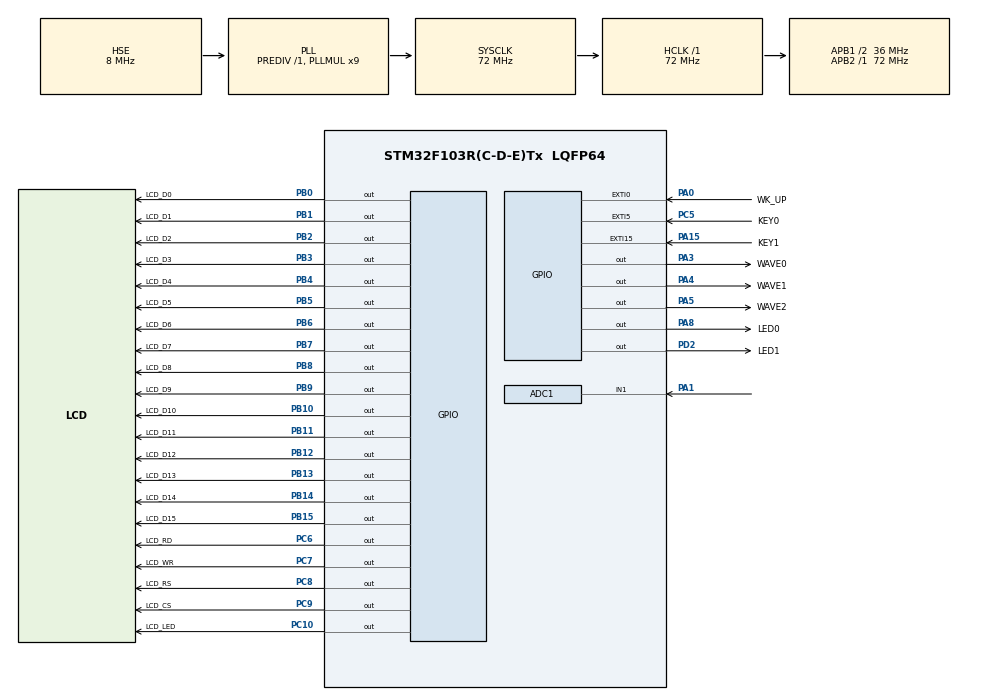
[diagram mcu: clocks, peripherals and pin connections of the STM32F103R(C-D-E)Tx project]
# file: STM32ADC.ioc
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ADC1.Channel-1\#ChannelRegularConversion=ADC_CHANNEL_1
ADC1.ContinuousConvMode=DISABLE
ADC1.EnableAnalogWatchDog=false
ADC1.EnableInjectedConversion=DISABLE
ADC1.EnableRegularConversion=ENABLE
ADC1.ExternalTrigConv=ADC_EXTERNALTRIGCONV_T3_TRGO
ADC1.InjNumberOfConversion=1
ADC1.NbrOfConversion=1
ADC1.NbrOfConversionFlag=1
ADC1.Rank-1\#ChannelRegularConversion=1
ADC1.SamplingTime-1\#ChannelRegularConversion=ADC_SAMPLETIME_7CYCLES_5
ADC1.master=1
Dma.ADC1.0.Direction=DMA_PERIPH_TO_MEMORY
Dma.ADC1.0.Instance=DMA1_Channel1
Dma.ADC1.0.MemDataAlignment=DMA_MDATAALIGN_HALFWORD
Dma.ADC1.0.MemInc=DMA_MINC_ENABLE
Dma.ADC1.0.Mode=DMA_CIRCULAR
Dma.ADC1.0.PeriphDataAlignment=DMA_PDATAALIGN_HALFWORD
Dma.ADC1.0.PeriphInc=DMA_PINC_DISABLE
Dma.ADC1.0.Priority=DMA_PRIORITY_VERY_HIGH
Dma.Request0=ADC1
Mcu.Family=STM32F1
Mcu.Name=STM32F103R(C-D-E)Tx
Mcu.Package=LQFP64
NVIC.DMA1_Channel1_IRQn=true\:1\:0\:true\:false\:true\:false\:true
NVIC.EXTI15_10_IRQn=true\:2\:2\:true\:false\:true\:true\:true
NVIC.EXTI9_5_IRQn=true\:2\:1\:true\:false\:true\:true\:true
NVIC.PriorityGroup=NVIC_PRIORITYGROUP_2
PA0-WKUP.GPIO_Label=WK_UP
PA0-WKUP.GPIO_ModeDefaultEXTI=GPIO_MODE_IT_RISING
PA0-WKUP.GPIO_PuPd=GPIO_PULLDOWN
PA0-WKUP.Signal=GPXTI0
PA1.Signal=ADCx_IN1
PA13.Mode=Serial_Wire
PA13.Signal=SYS_JTMS-SWDIO
PA14.Mode=Serial_Wire
PA14.Signal=SYS_JTCK-SWCLK
PA15.GPIO_Label=KEY1
PA15.GPIO_ModeDefaultEXTI=GPIO_MODE_IT_FALLING
PA15.GPIO_PuPd=GPIO_PULLUP
PA15.Signal=GPXTI15
PA3.GPIO_Label=WAVE0
PA3.Signal=GPIO_Output
PA4.GPIO_Label=WAVE1
PA4.Signal=GPIO_Output
PA5.GPIO_Label=WAVE2
PA5.Signal=GPIO_Output
PA8.GPIO_Label=LED0
PA8.Signal=GPIO_Output
PB0.GPIO_Label=LCD_D0
PB0.GPIO_ModeDefaultOutputPP=GPIO_MODE_OUTPUT_PP
PB0.GPIO_PuPd=GPIO_PULLUP
PB0.GPIO_Speed=GPIO_SPEED_FREQ_HIGH
PB0.PinState=GPIO_PIN_SET
PB0.Signal=GPIO_Output
PB1.GPIO_Label=LCD_D1
PB1.GPIO_PuPd=GPIO_PULLUP
PB1.GPIO_Speed=GPIO_SPEED_FREQ_HIGH
PB1.PinState=GPIO_PIN_SET
PB1.Signal=GPIO_Output
PB10.GPIO_Label=LCD_D10
PB10.GPIO_PuPd=GPIO_PULLUP
PB10.GPIO_Speed=GPIO_SPEED_FREQ_HIGH
PB10.PinState=GPIO_PIN_SET
PB10.Signal=GPIO_Output
PB11.GPIO_Label=LCD_D11
PB11.GPIO_PuPd=GPIO_PULLUP
PB11.GPIO_Speed=GPIO_SPEED_FREQ_HIGH
PB11.PinState=GPIO_PIN_SET
PB11.Signal=GPIO_Output
PB12.GPIO_Label=LCD_D12
PB12.GPIO_PuPd=GPIO_PULLUP
PB12.GPIO_Speed=GPIO_SPEED_FREQ_HIGH
PB12.PinState=GPIO_PIN_SET
PB12.Signal=GPIO_Output
PB13.GPIO_Label=LCD_D13
PB13.GPIO_PuPd=GPIO_PULLUP
PB13.GPIO_Speed=GPIO_SPEED_FREQ_HIGH
PB13.PinState=GPIO_PIN_SET
PB13.Signal=GPIO_Output
PB14.GPIO_Label=LCD_D14
PB14.GPIO_PuPd=GPIO_PULLUP
PB14.GPIO_Speed=GPIO_SPEED_FREQ_HIGH
PB14.PinState=GPIO_PIN_SET
PB14.Signal=GPIO_Output
PB15.GPIO_Label=LCD_D15
PB15.GPIO_PuPd=GPIO_PULLUP
PB15.GPIO_Speed=GPIO_SPEED_FREQ_HIGH
PB15.PinState=GPIO_PIN_SET
PB15.Signal=GPIO_Output
PB2.GPIO_Label=LCD_D2
PB2.GPIO_PuPd=GPIO_PULLUP
PB2.GPIO_Speed=GPIO_SPEED_FREQ_HIGH
PB2.PinState=GPIO_PIN_SET
PB2.Signal=GPIO_Output
PB3.GPIO_Label=LCD_D3
PB3.GPIO_ModeDefaultOutputPP=GPIO_MODE_OUTPUT_PP
PB3.GPIO_PuPd=GPIO_PULLUP
PB3.GPIO_Speed=GPIO_SPEED_FREQ_HIGH
PB3.PinState=GPIO_PIN_SET
PB3.Signal=GPIO_Output
PB4.GPIO_Label=LCD_D4
PB4.GPIO_PuPd=GPIO_PULLUP
PB4.GPIO_Speed=GPIO_SPEED_FREQ_HIGH
PB4.PinState=GPIO_PIN_SET
PB4.Signal=GPIO_Output
PB5.GPIO_Label=LCD_D5
PB5.GPIO_PuPd=GPIO_PULLUP
PB5.GPIO_Speed=GPIO_SPEED_FREQ_HIGH
PB5.PinState=GPIO_PIN_SET
PB5.Signal=GPIO_Output
PB6.GPIO_Label=LCD_D6
PB6.GPIO_PuPd=GPIO_PULLUP
PB6.GPIO_Speed=GPIO_SPEED_FREQ_HIGH
PB6.PinState=GPIO_PIN_SET
PB6.Signal=GPIO_Output
PB7.GPIO_Label=LCD_D7
PB7.GPIO_PuPd=GPIO_PULLUP
PB7.GPIO_Speed=GPIO_SPEED_FREQ_HIGH
PB7.PinState=GPIO_PIN_SET
PB7.Signal=GPIO_Output
PB8.GPIO_Label=LCD_D8
PB8.GPIO_PuPd=GPIO_PULLUP
PB8.GPIO_Speed=GPIO_SPEED_FREQ_HIGH
PB8.PinState=GPIO_PIN_SET
PB8.Signal=GPIO_Output
PB9.GPIO_Label=LCD_D9
PB9.GPIO_PuPd=GPIO_PULLUP
PB9.GPIO_Speed=GPIO_SPEED_FREQ_HIGH
PB9.PinState=GPIO_PIN_SET
PB9.Signal=GPIO_Output
PC10.GPIO_Label=LCD_LED
PC10.GPIO_ModeDefaultOutputPP=GPIO_MODE_OUTPUT_PP
PC10.GPIO_PuPd=GPIO_PULLUP
PC10.GPIO_Speed=GPIO_SPEED_FREQ_HIGH
PC10.PinState=GPIO_PIN_SET
PC10.Signal=GPIO_Output
PC5.GPIO_Label=KEY0
PC5.GPIO_ModeDefaultEXTI=GPIO_MODE_IT_FALLING
PC5.GPIO_PuPd=GPIO_PULLUP
PC5.Signal=GPXTI5
PC6.GPIO_Label=LCD_RD
PC6.GPIO_ModeDefaultOutputPP=GPIO_MODE_OUTPUT_PP
PC6.GPIO_PuPd=GPIO_PULLUP
PC6.GPIO_Speed=GPIO_SPEED_FREQ_HIGH
PC6.PinState=GPIO_PIN_SET
PC6.Signal=GPIO_Output
PC7.GPIO_Label=LCD_WR
PC7.GPIO_PuPd=GPIO_PULLUP
PC7.GPIO_Speed=GPIO_SPEED_FREQ_HIGH
PC7.PinState=GPIO_PIN_SET
PC7.Signal=GPIO_Output
PC8.GPIO_Label=LCD_RS
PC8.GPIO_ModeDefaultOutputPP=GPIO_MODE_OUTPUT_PP
PC8.GPIO_PuPd=GPIO_PULLUP
PC8.GPIO_Speed=GPIO_SPEED_FREQ_HIGH
PC8.PinState=GPIO_PIN_SET
PC8.Signal=GPIO_Output
PC9.GPIO_Label=LCD_CS
PC9.GPIO_PuPd=GPIO_PULLUP
PC9.GPIO_Speed=GPIO_SPEED_FREQ_HIGH
PC9.PinState=GPIO_PIN_SET
PC9.Signal=GPIO_Output
PD0-OSC_IN.Mode=HSE-External-Oscillator
PD0-OSC_IN.Signal=RCC_OSC_IN
PD1-OSC_OUT.Mode=HSE-External-Oscillator
PD1-OSC_OUT.Signal=RCC_OSC_OUT
PD2.GPIO_Label=LED1
PD2.Signal=GPIO_Output
ProjectManager.HeapSize=0x200
ProjectManager.StackSize=0x400
ProjectManager.TargetToolchain=MDK-ARM V5.27
RCC.ADCPresc=RCC_ADCPCLK2_DIV6
RCC.AHBFreq_Value=72000000
RCC.APB1CLKDivider=RCC_HCLK_DIV2
RCC.APB1Freq_Value=36000000
RCC.APB1TimFreq_Value=72000000
RCC.APB2Freq_Value=72000000
RCC.APB2TimFreq_Value=72000000
RCC.HCLKFreq_Value=72000000
RCC.PLLMUL=RCC_PLL_MUL9
RCC.PLLSourceVirtual=RCC_PLLSOURCE_HSE
RCC.SYSCLKFreq_VALUE=72000000
RCC.SYSCLKSource=RCC_SYSCLKSOURCE_PLLCLK
RCC.USBFreq_Value=72000000
SH.ADCx_IN1.0=ADC1_IN1,IN1
TIM3.AutoReloadPreload=TIM_AUTORELOAD_PRELOAD_ENABLE
TIM3.Period=100
TIM3.Prescaler=35
TIM3.TIM_MasterOutputTrigger=TIM_TRGO_UPDATE
VP_TIM3_VS_ClockSourceINT.Mode=Internal
board=custom

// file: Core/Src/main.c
/* USER CODE BEGIN Header */
/**
  ******************************************************************************
  * @file           : main.c
  * @brief          : Main program body
  ******************************************************************************
  * @attention
  *
  * <h2><center>&copy; Copyright (c) 2020 STMicroelectronics.
  * All rights reserved.</center></h2>
  *
  * This software component is licensed by ST under BSD 3-Clause license,
  * the "License"; You may not use this file except in compliance with the
  * License. You may obtain a copy of the License at:
  *                        opensource.org/licenses/BSD-3-Clause
  *
  ******************************************************************************
  */
/* USER CODE END Header */
#include "main.h"
#include "adc.h"
#include "dma.h"
#include "tim.h"
#include "gpio.h"

/* USER CODE BEGIN Includes */
#include "dso.h"
#include "lcd.h"
#include "STM32_WaveOutput.h"
/* USER CODE END Includes */

void SystemClock_Config(void);

int main(void)
{

  /* MCU Configuration--------------------------------------------------------*/

  /* Reset of all peripherals, Initializes the Flash interface and the Systick. */
  HAL_Init();

  /* Configure the system clock */
  SystemClock_Config();

  /* Initialize all configured peripherals */
  MX_GPIO_Init();
  MX_DMA_Init();
  MX_ADC1_Init();
  MX_TIM3_Init();
  /* USER CODE BEGIN 2 */

  //示波器测试用的波形输出
  //输出频率为1KHz的三种波形：PA3输出方波，PA4输出三角波，PA5输出正弦波
  //测试时用杜邦线将ADC的输入引脚与输出波形引脚连接
  //方波峰峰值Vpp=3.3，三角波Vpp=3.24，正弦波Vpp=2.6
  TestWave_Init();
  //注意：这里测试波形产生未在CUBEMX中配置，已使用资源：定时器2、定时器5、定时器6、DAC通道1-2、DMA2通道3-4

  LCD_Init();
  DSO_Init();

  run_sta=1; //启动示波器

  /* USER CODE END 2 */

  /* Infinite loop */
  /* USER CODE BEGIN WHILE */
  while (1)
  {

	//主要代码都在DMA中断里调用

    /* USER CODE END WHILE */

  }
}

void SystemClock_Config(void)
{
  RCC_OscInitTypeDef RCC_OscInitStruct = {0};
  RCC_ClkInitTypeDef RCC_ClkInitStruct = {0};
  RCC_PeriphCLKInitTypeDef PeriphClkInit = {0};

  /** Initializes the RCC Oscillators according to the specified parameters
  * in the RCC_OscInitTypeDef structure.
  */
  RCC_OscInitStruct.OscillatorType = RCC_OSCILLATORTYPE_HSE;
  RCC_OscInitStruct.HSEState = RCC_HSE_ON;
  RCC_OscInitStruct.HSEPredivValue = RCC_HSE_PREDIV_DIV1;
  RCC_OscInitStruct.HSIState = RCC_HSI_ON;
  RCC_OscInitStruct.PLL.PLLState = RCC_PLL_ON;
  RCC_OscInitStruct.PLL.PLLSource = RCC_PLLSOURCE_HSE;
  RCC_OscInitStruct.PLL.PLLMUL = RCC_PLL_MUL9;
  if (HAL_RCC_OscConfig(&RCC_OscInitStruct) != HAL_OK)
  {
    Error_Handler();
  }
  /** Initializes the CPU, AHB and APB buses clocks
  */
  RCC_ClkInitStruct.ClockType = RCC_CLOCKTYPE_HCLK|RCC_CLOCKTYPE_SYSCLK
                              |RCC_CLOCKTYPE_PCLK1|RCC_CLOCKTYPE_PCLK2;
  RCC_ClkInitStruct.SYSCLKSource = RCC_SYSCLKSOURCE_PLLCLK;
  RCC_ClkInitStruct.AHBCLKDivider = RCC_SYSCLK_DIV1;
  RCC_ClkInitStruct.APB1CLKDivider = RCC_HCLK_DIV2;
  RCC_ClkInitStruct.APB2CLKDivider = RCC_HCLK_DIV1;

  if (HAL_RCC_ClockConfig(&RCC_ClkInitStruct, FLASH_LATENCY_2) != HAL_OK)
  {
    Error_Handler();
  }
  PeriphClkInit.PeriphClockSelection = RCC_PERIPHCLK_ADC;
  PeriphClkInit.AdcClockSelection = RCC_ADCPCLK2_DIV6;
  if (HAL_RCCEx_PeriphCLKConfig(&PeriphClkInit) != HAL_OK)
  {
    Error_Handler();
  }
}

void Error_Handler(void)
{
  __disable_irq();
  while (1)
  {
  }
}

/************************ (C) COPYRIGHT STMicroelectronics *****END OF FILE****/
